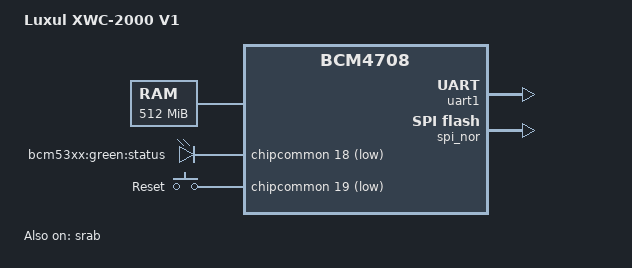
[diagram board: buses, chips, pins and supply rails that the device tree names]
// SPDX-License-Identifier: GPL-2.0-or-later OR MIT
/*
 * Copyright 2019 Legrand AV Inc.
 */

/dts-v1/;

#include "bcm47094.dtsi"
#include "bcm5301x-nand-cs0-bch8.dtsi"

/ {
	compatible = "luxul,xwc-2000-v1", "brcm,bcm47094", "brcm,bcm4708";
	model = "Luxul XWC-2000 V1";

	chosen {
		bootargs = "earlycon";
	};

	memory@0 {
		device_type = "memory";
		reg = <0x00000000 0x08000000>,
		      <0x88000000 0x18000000>;
	};

	nvram@1eff0000 {
		compatible = "brcm,nvram";
		reg = <0x1eff0000 0x10000>;

		et0macaddr: et0macaddr {
		};
	};

	leds {
		compatible = "gpio-leds";

		led-status {
			label = "bcm53xx:green:status";
			gpios = <&chipcommon 18 GPIO_ACTIVE_LOW>;
			linux,default-trigger = "timer";
		};
	};

	gpio-keys {
		compatible = "gpio-keys";

		button-restart {
			label = "Reset";
			linux,code = <KEY_RESTART>;
			gpios = <&chipcommon 19 GPIO_ACTIVE_LOW>;
		};
	};
};

&uart1 {
	status = "okay";
};

&gmac0 {
	nvmem-cells = <&et0macaddr>;
	nvmem-cell-names = "mac-address";
};

&spi_nor {
	status = "okay";
};

&srab {
	status = "okay";

	ports {
		port@0 {
			label = "lan";
		};

		port@5 {
			label = "cpu";
		};

		port@7 {
			status = "disabled";
		};

		port@8 {
			status = "disabled";
		};
	};
};
